# CYBLE_416045_02 register map
File version: 0.1
PSoC 63
Registers are 32-bit, read-write, no defined reset value unless marked. A register's access mark holds for its fields unless they carry their own. Offsets are from the block's base; lines under a group give offsets from that group; [hi:lo] are bit positions; {n}, {i} and the like mark numbered series; 'fields as' and 'values as' point back to an identical list; <NAME> marks a mode.

## Memory map
0x00000000 VDAC
0x00000000 I2C

## VDAC
Base 0x00000000
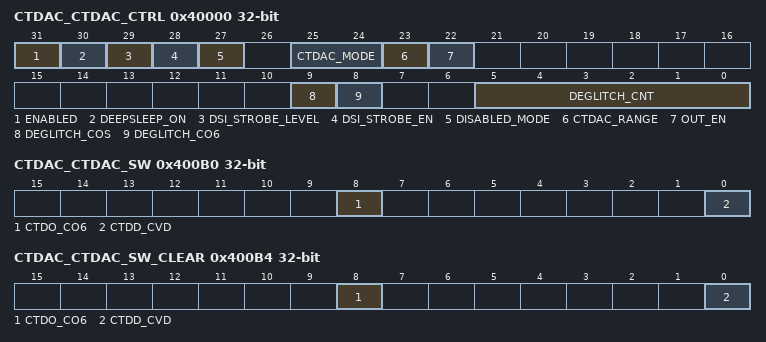
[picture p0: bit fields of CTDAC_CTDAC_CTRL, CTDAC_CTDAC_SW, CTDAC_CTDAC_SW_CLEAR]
0x40000 CTDAC_CTDAC_CTRL — Global CTDAC control
  [31] ENABLED — 0: CTDAC IP disabled (put analog in power down, open all switches)?1: CTDAC IP enabled
  [30] DEEPSLEEP_ON — - 0: CTDAC IP disabled off during DeepSleep power mode?- 1: CTDAC IP remains enabled during DeepSleep power mode (if ENABLED=1)
  [29] DSI_STROBE_LEVEL — Select level or edge detect for DSI strobe?- 0: DSI strobe signal is a pulse input, after a positive edge is detected on the DSI strobe signal the next DAC value update is done on the next CTDAC clock?- 1: DSI strobe signal is a level input, as long as the DSI strobe signal remains high the CTDAC will do a next DAC value update on each CTDAC clock.
  [28] DSI_STROBE_EN — DSI strobe input Enable. This enables CTDAC updates to be further throttled by DSI.?0: Ignore DSI strobe input?1: Only do a CTDAC update if alllowed by the DSI stobe (throttle), see below for level or edge
  [27] DISABLED_MODE — Select the output value when the output is disabled (OUT_EN=0) (for risk mitigation)?0: Tri-state CTDAC output when disabled?1: output Vssa or Vref when disabled (see OUT_EN description)
  [25:24] CTDAC_MODE — DAC mode, this determines the Value decoding
    0=UNSIGNED12 (Unsigned 12-bit VDAC, i.e. no value decoding.); 1=VIRT_SIGNED12 (Virtual signed 12-bits' VDAC. Value decoding: ?add 0x800 to the 12-bit Value (=invert MSB), to convert the lowest signed number 0x800 to the lowest unsigned number 0x000. This is the same as the SAR handles 12-bit 'virtual' signed numbers.)
  [23] CTDAC_RANGE — By closing the bottom switch in the R2R network the output is lifted by one LSB, effectively adding 1?0: Range is [0, 4095] * Vref / 4096 ?1: Range is [1, 4096] * Vref / 4096
  [22] OUT_EN — Output enable, intended to be used during the Hold phase of the Sample and Hold when power cycling :?0: output disabled, the output is either: ? - Tri-state (DISABLED_MODE=0) ? - or Vssa (DISABLED_MODE=1 && CTDAC_RANGE=0) ? - or Vref (DISABLED_MODE=1 && CTDAC_RANGE=1) ?1: output enabled, CTDAC output drives the programmed VALUE
  [9] DEGLITCH_COS — Force CTB.COS switch open after each VALUE change for the set number of clock cycles.
  [8] DEGLITCH_CO6 — Force CTDAC.CO6 switch open after each VALUE change for the set number of clock cycles.
  [5:0] DEGLITCH_CNT — To prevent glitches after VALUE changes from propagating, the output switch can be opened for DEGLITCH_CNT+1 clk_ctdac clock cycles.
0x40020 CTDAC_INTR — Interrupt request register
  [0] VDAC_EMPTY — VDAC Interrupt: hardware sets this interrupt when VDAC next value field is empty, i.e. was copied to the current VALUE. Write with '1' to clear bit.
0x40024 CTDAC_INTR_SET — Interrupt request set register
  [0] VDAC_EMPTY_SET — Write with '1' to set corresponding bit in interrupt request register.
0x40028 CTDAC_INTR_MASK — Interrupt request mask
  [0] VDAC_EMPTY_MASK — Mask bit for corresponding bit in interrupt request register.
0x4002C CTDAC_INTR_MASKED — Interrupt request masked
  [0] VDAC_EMPTY_MASKED ro — Logical and of corresponding request and mask bits.
0x400B0 CTDAC_CTDAC_SW — CTDAC switch control
  [8] CTDO_CO6 — ctdvout to P6 pin. Note this switch will temporarily be opened for deglitching if DEGLITCH_CO6 is set
  [0] CTDD_CVD — VDDA supply to ctdrefdrive
0x400B4 CTDAC_CTDAC_SW_CLEAR — CTDAC switch control clear
  [8] CTDO_CO6 — see corresponding bit in CTD_SW
  [0] CTDD_CVD — see corresponding bit in CTD_SW
0x40100 CTDAC_CTDAC_VAL — DAC Value
  [11:0] VALUE — Value, in CTDAC_MODE 1 this value is decoded
0x40104 CTDAC_CTDAC_VAL_NXT — Next DAC value (double buffering)
  [11:0] VALUE — Next value for CTDAC_VAL.VALUE

## I2C
Base 0x00000000
0x40341018 I2C_DATA 8-bit
  [7:0] data — Read received data or write data to transmit.
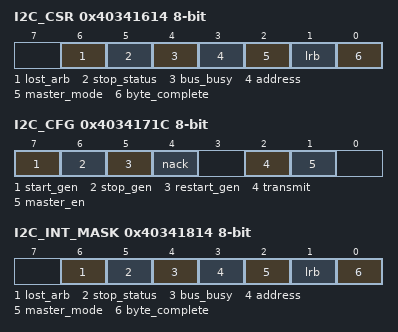
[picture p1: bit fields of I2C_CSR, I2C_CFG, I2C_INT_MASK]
0x40341614 I2C_CSR 8-bit — I2C Status Register
  [6] lost_arb ro — If set, indicates arbitration was lost (multi-master and multi-master-slave modes).
  [5] stop_status ro — If set, indicates a Stop condition was detected on the bus.
  [4] bus_busy ro — If set, indicates the bus is busy. Data is currently being transmitted or received.
  [3] address ro — Address detection. If set, indicates that an address byte was sent.
  [2] master_mode ro — Indicates that a valid Start condition was generated and a hardware device is operating as bus master.
  [1] lrb ro — Last Received Bit. Indicates the state of the last received bit, which is the ACK/NAK received for the last byte transmitted. Cleared = ACK and set = NAK.
  [0] byte_complete ro — Transmit or receive status since the last read of this register. In Transmit mode this bit indicates that eight bits of data plus ACK/NAK have been transmitted since the last read. In Receive mode this bit indicates that eight bits of data have been received since the last read of this register.
0x4034171C I2C_CFG 8-bit — I2C Configuration Register
  [7] start_gen — Set to 1 to generate a Start condition on the bus. This bit must be cleared by firmware before initiating the next transaction.
  [6] stop_gen — Set to 1 to generate a Stop condition on the bus. This bit must be cleared by firmware before initiating the next transaction.
  [5] restart_gen — Set to 1 to generate a Restart condition on the bus. This bit must be cleared by firmware after a Restart condition is generated.
  [4] nack — Set to 1 to NAK the next read byte. Clear to ACK next read byte. This bit must be cleared by firmware between bytes.
  [2] transmit — Set to 1 to set the current mode to transmit or clear to 0 to receive a byte of data. This bit must be cleared by firmware before starting the next transmit or receive transaction.
  [1] master_en — Set to 1 to enable the master functionality.
0x40341814 I2C_INT_MASK 8-bit — I2C Interrupt Enable Mask
  [6] lost_arb — Enables interrupt from the corresponding bit in status register.
  [5] stop_status — Enables interrupt from the corresponding bit in status register.
  [4] bus_busy — Enables interrupt from the corresponding bit in status register.
  [3] address — Enables interrupt from the corresponding bit in status register.
  [2] master_mode — Enables interrupt from the corresponding bit in status register.
  [1] lrb — Enables interrupt from the corresponding bit in status register.
  [0] byte_complete — Enables interrupt from the corresponding bit in status register.
